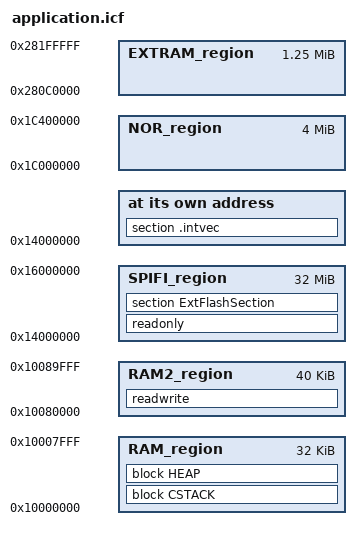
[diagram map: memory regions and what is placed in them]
/*###ICF### Section handled by ICF editor, don't touch! ****/
/*-Editor annotation file-*/
/* IcfEditorFile="$TOOLKIT_DIR$\config\ide\IcfEditor\cortex_v1_0.xml" */
/*-Specials-*/
define symbol __ICFEDIT_intvec_start__ = 0x14000000; /*0x1A000000;*/
/*-Memory Regions-*/

/*define symbol __ICFEDIT_region_ROM_start__ = 0x1A000116;
define symbol __ICFEDIT_region_ROM_end__   = 0x1A07FFFF;*/

define symbol __ICFEDIT_region_RAM_start__ = 0x10000000;
define symbol __ICFEDIT_region_RAM_end__   = 0x10007FFF;

/*-Sizes-*/
define symbol __ICFEDIT_size_cstack__ = 0x2000;
define symbol __ICFEDIT_size_heap__   = 0x6000;
/**** End of ICF editor section. ###ICF###*/

/********* SPIFI REGION *********/

/* define symbol __ICFEDIT_size_heap__   = 0x100000; */

define symbol __SPIFI_start__ = 0x14000000;
define symbol __SPIFI_end__   = 0x16000000;

define symbol __NOR_start__ = 0x1C000000;
define symbol __NOR_end__   = 0x1C400000;

define symbol __SRAM2_start__ = 0x10080000;
define symbol __SRAM2_end__   = 0x10089FFF;

define symbol __EXTRAM_start__ = 0x280C0000;
define symbol __EXTRAM_end__   = 0x281FFFFF;

define memory mem with size = 4G;
/*define region ROM_region           = mem:[from __ICFEDIT_region_ROM_start__   to __ICFEDIT_region_ROM_end__];*/
define region RAM_region           = mem:[from __ICFEDIT_region_RAM_start__   to __ICFEDIT_region_RAM_end__];
define region SPIFI_region         = mem:[from  __SPIFI_start__ to __SPIFI_end__];
define region NOR_region           = mem:[from  __NOR_start__ to __NOR_end__];
define region RAM2_region          = mem:[from  __SRAM2_start__ to __SRAM2_end__];
define region EXTRAM_region        = mem:[from  __EXTRAM_start__ to __EXTRAM_end__];   

define block CSTACK    with alignment = 8, size = __ICFEDIT_size_cstack__   { };
define block HEAP      with alignment = 8, size = __ICFEDIT_size_heap__     { };

initialize by copy { readwrite }; 
do not initialize  { section .noinit };
do not initialize  { section .eeprom }; 

place at address mem:__ICFEDIT_intvec_start__ { section .intvec };

place in RAM_region { block CSTACK, block HEAP };

/*
place in RAM_region { block CSTACK };
place in EXTRAM_region { block HEAP};
*/

place in SPIFI_region            { readonly };
place in SPIFI_region            { section ExtFlashSection };
place in RAM2_region             { readwrite };

/*place in NOR_region            { section ExtFlashSection };*/
/*place in ROM_region            { readonly };*/
